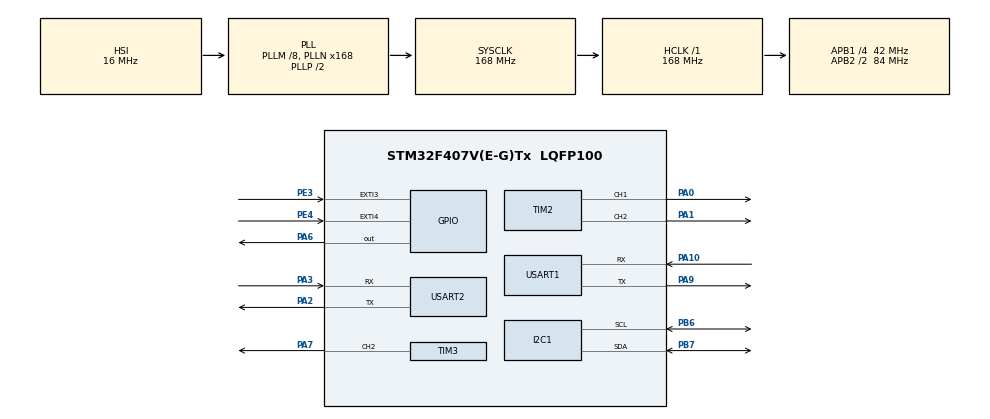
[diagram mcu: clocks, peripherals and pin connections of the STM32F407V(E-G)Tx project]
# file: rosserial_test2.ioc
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Dma.Request0=USART1_RX
Dma.Request1=USART1_TX
Dma.USART1_RX.0.Direction=DMA_PERIPH_TO_MEMORY
Dma.USART1_RX.0.FIFOMode=DMA_FIFOMODE_DISABLE
Dma.USART1_RX.0.Instance=DMA2_Stream2
Dma.USART1_RX.0.MemDataAlignment=DMA_MDATAALIGN_BYTE
Dma.USART1_RX.0.MemInc=DMA_MINC_ENABLE
Dma.USART1_RX.0.Mode=DMA_NORMAL
Dma.USART1_RX.0.PeriphDataAlignment=DMA_PDATAALIGN_BYTE
Dma.USART1_RX.0.PeriphInc=DMA_PINC_DISABLE
Dma.USART1_RX.0.Priority=DMA_PRIORITY_HIGH
Dma.USART1_TX.1.Direction=DMA_MEMORY_TO_PERIPH
Dma.USART1_TX.1.FIFOMode=DMA_FIFOMODE_DISABLE
Dma.USART1_TX.1.Instance=DMA2_Stream7
Dma.USART1_TX.1.MemDataAlignment=DMA_MDATAALIGN_BYTE
Dma.USART1_TX.1.MemInc=DMA_MINC_ENABLE
Dma.USART1_TX.1.Mode=DMA_NORMAL
Dma.USART1_TX.1.PeriphDataAlignment=DMA_PDATAALIGN_BYTE
Dma.USART1_TX.1.PeriphInc=DMA_PINC_DISABLE
Dma.USART1_TX.1.Priority=DMA_PRIORITY_HIGH
Mcu.Family=STM32F4
Mcu.Name=STM32F407V(E-G)Tx
Mcu.Package=LQFP100
NVIC.DMA2_Stream2_IRQn=true\:0\:0\:false\:false\:true\:false\:true
NVIC.DMA2_Stream7_IRQn=true\:0\:0\:false\:false\:true\:false\:true
NVIC.EXTI3_IRQn=true\:0\:0\:false\:false\:true\:true\:true
NVIC.EXTI4_IRQn=true\:0\:0\:false\:false\:true\:true\:true
NVIC.PriorityGroup=NVIC_PRIORITYGROUP_4
NVIC.USART1_IRQn=true\:0\:0\:false\:false\:true\:true\:true
PA0-WKUP.Signal=S_TIM2_CH1_ETR
PA1.Signal=S_TIM2_CH2
PA10.Mode=Asynchronous
PA10.Signal=USART1_RX
PA2.Mode=Asynchronous
PA2.Signal=USART2_TX
PA3.Mode=Asynchronous
PA3.Signal=USART2_RX
PA6.Signal=GPIO_Output
PA7.Signal=S_TIM3_CH2
PA9.Mode=Asynchronous
PA9.Signal=USART1_TX
PB6.Mode=I2C
PB6.Signal=I2C1_SCL
PB7.Mode=I2C
PB7.Signal=I2C1_SDA
PE3.Signal=GPXTI3
PE4.Signal=GPXTI4
PH0-OSC_IN.Mode=HSE-External-Oscillator
PH0-OSC_IN.Signal=RCC_OSC_IN
PH1-OSC_OUT.Mode=HSE-External-Oscillator
PH1-OSC_OUT.Signal=RCC_OSC_OUT
ProjectManager.HeapSize=0x200
ProjectManager.StackSize=0x400
ProjectManager.TargetToolchain=STM32CubeIDE
RCC.48MHZClocksFreq_Value=84000000
RCC.AHBFreq_Value=168000000
RCC.APB1CLKDivider=RCC_HCLK_DIV4
RCC.APB1Freq_Value=42000000
RCC.APB1TimFreq_Value=84000000
RCC.APB2CLKDivider=RCC_HCLK_DIV2
RCC.APB2Freq_Value=84000000
RCC.APB2TimFreq_Value=168000000
RCC.CortexFreq_Value=168000000
RCC.HCLKFreq_Value=168000000
RCC.HSE_VALUE=8000000
RCC.HSI_VALUE=16000000
RCC.LSE_VALUE=32768
RCC.PLLM=8
RCC.PLLN=168
RCC.SYSCLKFreq_VALUE=168000000
RCC.SYSCLKSource=RCC_SYSCLKSOURCE_PLLCLK
RCC.VCOOutputFreq_Value=336000000
SH.S_TIM2_CH1_ETR.0=TIM2_CH1,PWM Generation1 CH1
SH.S_TIM2_CH2.0=TIM2_CH2,PWM Generation2 CH2
SH.S_TIM3_CH2.0=TIM3_CH2,PWM Generation2 CH2
TIM2.Channel-PWM\ Generation1\ CH1=TIM_CHANNEL_1
TIM2.Channel-PWM\ Generation2\ CH2=TIM_CHANNEL_2
TIM3.Channel-PWM\ Generation2\ CH2=TIM_CHANNEL_2
USART1.VirtualMode=VM_ASYNC
USART2.VirtualMode=VM_ASYNC
VP_TIM2_VS_ClockSourceINT.Mode=Internal
VP_TIM3_VS_ClockSourceINT.Mode=Internal
board=custom

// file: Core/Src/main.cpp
/* USER CODE BEGIN Header */
/**
  ******************************************************************************
  * @file           : main.c
  * @brief          : Main program body
  ******************************************************************************
  * @attention
  *
  * <h2><center>&copy; Copyright (c) 2020 STMicroelectronics.
  * All rights reserved.</center></h2>
  *
  * This software component is licensed by ST under BSD 3-Clause license,
  * the "License"; You may not use this file except in compliance with the
  * License. You may obtain a copy of the License at:
  *                        opensource.org/licenses/BSD-3-Clause
  *
  ******************************************************************************
  */
/* USER CODE END Header */

#include "main.h"
#include <ros.h>
#include <std_msgs/String.h>

ros::NodeHandle nh;

std_msgs::String str_msg;
ros::Publisher chatter("chatter", &str_msg);
char hello[] = "Hello world!";

void HAL_UART_TxCpltCallback(UART_HandleTypeDef *huart){
  nh.getHardware()->flush();
}

void HAL_UART_RxCpltCallback(UART_HandleTypeDef *huart){
  nh.getHardware()->reset_rbuf();
}

I2C_HandleTypeDef hi2c1;

TIM_HandleTypeDef htim2;
TIM_HandleTypeDef htim3;

UART_HandleTypeDef huart1;
UART_HandleTypeDef huart2;
DMA_HandleTypeDef hdma_usart1_rx;
DMA_HandleTypeDef hdma_usart1_tx;

void SystemClock_Config(void);
static void MX_GPIO_Init(void);
static void MX_I2C1_Init(void);
static void MX_TIM2_Init(void);
static void MX_TIM3_Init(void);
static void MX_DMA_Init(void);
static void MX_USART1_UART_Init(void);
static void MX_USART2_UART_Init(void);

int main(void)
{

  /* MCU Configuration--------------------------------------------------------*/

  /* Reset of all peripherals, Initializes the Flash interface and the Systick. */
  HAL_Init();

  /* Configure the system clock */
  SystemClock_Config();

  /* Initialize all configured peripherals */
  MX_GPIO_Init();
  MX_DMA_Init();
  MX_I2C1_Init();
  MX_TIM2_Init();
  MX_TIM3_Init();
  MX_USART1_UART_Init();
  MX_USART2_UART_Init();
  /* USER CODE BEGIN 2 */
  nh.initNode();
  nh.advertise(chatter);
  HAL_TIM_PWM_Start(&htim2, TIM_CHANNEL_1);
  HAL_TIM_PWM_Start(&htim2, TIM_CHANNEL_2);
  HAL_TIM_PWM_Start(&htim3, TIM_CHANNEL_2);
  /* USER CODE END 2 */

  /* Infinite loop */
  /* USER CODE BEGIN WHILE */
  uint16_t ccr = 0;
  while (1)
  {
    /* USER CODE END WHILE */
	  str_msg.data = hello;
	  chatter.publish(&str_msg);

	  TIM3->CCR2 = ccr;
	  ccr += 1000;
	  if (ccr > TIM3->ARR) ccr = 0;
//	  HAL_GPIO_WritePin(GPIOA, GPIO_PIN_6, GPIO_PIN_RESET);
//	  HAL_Delay(2000);
//
//	  HAL_GPIO_WritePin(GPIOA, GPIO_PIN_6, GPIO_PIN_SET);

	  nh.spinOnce();
	  HAL_Delay(50);
  }
}

void SystemClock_Config(void)
{
  RCC_OscInitTypeDef RCC_OscInitStruct = {0};
  RCC_ClkInitTypeDef RCC_ClkInitStruct = {0};

  /** Configure the main internal regulator output voltage
  */
  __HAL_RCC_PWR_CLK_ENABLE();
  __HAL_PWR_VOLTAGESCALING_CONFIG(PWR_REGULATOR_VOLTAGE_SCALE1);
  /** Initializes the CPU, AHB and APB busses clocks
  */
  RCC_OscInitStruct.OscillatorType = RCC_OSCILLATORTYPE_HSI;
  RCC_OscInitStruct.HSIState = RCC_HSI_ON;
  RCC_OscInitStruct.HSICalibrationValue = RCC_HSICALIBRATION_DEFAULT;
  RCC_OscInitStruct.PLL.PLLState = RCC_PLL_ON;
  RCC_OscInitStruct.PLL.PLLSource = RCC_PLLSOURCE_HSI;
  RCC_OscInitStruct.PLL.PLLM = 8;
  RCC_OscInitStruct.PLL.PLLN = 168;
  RCC_OscInitStruct.PLL.PLLP = RCC_PLLP_DIV2;
  RCC_OscInitStruct.PLL.PLLQ = 4;
  if (HAL_RCC_OscConfig(&RCC_OscInitStruct) != HAL_OK)
  {
    Error_Handler();
  }
  /** Initializes the CPU, AHB and APB busses clocks
  */
  RCC_ClkInitStruct.ClockType = RCC_CLOCKTYPE_HCLK|RCC_CLOCKTYPE_SYSCLK
                              |RCC_CLOCKTYPE_PCLK1|RCC_CLOCKTYPE_PCLK2;
  RCC_ClkInitStruct.SYSCLKSource = RCC_SYSCLKSOURCE_PLLCLK;
  RCC_ClkInitStruct.AHBCLKDivider = RCC_SYSCLK_DIV1;
  RCC_ClkInitStruct.APB1CLKDivider = RCC_HCLK_DIV4;
  RCC_ClkInitStruct.APB2CLKDivider = RCC_HCLK_DIV2;

  if (HAL_RCC_ClockConfig(&RCC_ClkInitStruct, FLASH_LATENCY_5) != HAL_OK)
  {
    Error_Handler();
  }
}

static void MX_I2C1_Init(void)
{

  hi2c1.Instance = I2C1;
  hi2c1.Init.ClockSpeed = 100000;
  hi2c1.Init.DutyCycle = I2C_DUTYCYCLE_2;
  hi2c1.Init.OwnAddress1 = 0;
  hi2c1.Init.AddressingMode = I2C_ADDRESSINGMODE_7BIT;
  hi2c1.Init.DualAddressMode = I2C_DUALADDRESS_DISABLE;
  hi2c1.Init.OwnAddress2 = 0;
  hi2c1.Init.GeneralCallMode = I2C_GENERALCALL_DISABLE;
  hi2c1.Init.NoStretchMode = I2C_NOSTRETCH_DISABLE;
  if (HAL_I2C_Init(&hi2c1) != HAL_OK)
  {
    Error_Handler();
  }

}

static void MX_TIM2_Init(void)
{

  TIM_ClockConfigTypeDef sClockSourceConfig = {0};
  TIM_MasterConfigTypeDef sMasterConfig = {0};
  TIM_OC_InitTypeDef sConfigOC = {0};

  htim2.Instance = TIM2;
  htim2.Init.Prescaler = 20-1;
  htim2.Init.CounterMode = TIM_COUNTERMODE_UP;
  htim2.Init.Period = 42000-1;
  htim2.Init.ClockDivision = TIM_CLOCKDIVISION_DIV1;
  htim2.Init.AutoReloadPreload = TIM_AUTORELOAD_PRELOAD_DISABLE;
  if (HAL_TIM_Base_Init(&htim2) != HAL_OK)
  {
    Error_Handler();
  }
  sClockSourceConfig.ClockSource = TIM_CLOCKSOURCE_INTERNAL;
  if (HAL_TIM_ConfigClockSource(&htim2, &sClockSourceConfig) != HAL_OK)
  {
    Error_Handler();
  }
  if (HAL_TIM_PWM_Init(&htim2) != HAL_OK)
  {
    Error_Handler();
  }
  sMasterConfig.MasterOutputTrigger = TIM_TRGO_RESET;
  sMasterConfig.MasterSlaveMode = TIM_MASTERSLAVEMODE_DISABLE;
  if (HAL_TIMEx_MasterConfigSynchronization(&htim2, &sMasterConfig) != HAL_OK)
  {
    Error_Handler();
  }
  sConfigOC.OCMode = TIM_OCMODE_PWM1;
  sConfigOC.Pulse = 21000-1;
  sConfigOC.OCPolarity = TIM_OCPOLARITY_HIGH;
  sConfigOC.OCFastMode = TIM_OCFAST_DISABLE;
  if (HAL_TIM_PWM_ConfigChannel(&htim2, &sConfigOC, TIM_CHANNEL_1) != HAL_OK)
  {
    Error_Handler();
  }
  sConfigOC.Pulse = 10500-1;
  if (HAL_TIM_PWM_ConfigChannel(&htim2, &sConfigOC, TIM_CHANNEL_2) != HAL_OK)
  {
    Error_Handler();
  }
  HAL_TIM_MspPostInit(&htim2);

}

static void MX_TIM3_Init(void)
{

  TIM_ClockConfigTypeDef sClockSourceConfig = {0};
  TIM_MasterConfigTypeDef sMasterConfig = {0};
  TIM_OC_InitTypeDef sConfigOC = {0};

  htim3.Instance = TIM3;
  htim3.Init.Prescaler = 20-1; // 주기
  htim3.Init.CounterMode = TIM_COUNTERMODE_UP;
  htim3.Init.Period = 42000-1;
  htim3.Init.ClockDivision = TIM_CLOCKDIVISION_DIV1;
  htim3.Init.AutoReloadPreload = TIM_AUTORELOAD_PRELOAD_DISABLE;
  if (HAL_TIM_Base_Init(&htim3) != HAL_OK)
  {
    Error_Handler();
  }
  sClockSourceConfig.ClockSource = TIM_CLOCKSOURCE_INTERNAL;
  if (HAL_TIM_ConfigClockSource(&htim3, &sClockSourceConfig) != HAL_OK)
  {
    Error_Handler();
  }
  if (HAL_TIM_PWM_Init(&htim3) != HAL_OK)
  {
    Error_Handler();
  }
  sMasterConfig.MasterOutputTrigger = TIM_TRGO_RESET;
  sMasterConfig.MasterSlaveMode = TIM_MASTERSLAVEMODE_DISABLE;
  if (HAL_TIMEx_MasterConfigSynchronization(&htim3, &sMasterConfig) != HAL_OK)
  {
    Error_Handler();
  }
  sConfigOC.OCMode = TIM_OCMODE_PWM1;
  sConfigOC.Pulse = 21000-1;// 펄스 폭
  sConfigOC.OCPolarity = TIM_OCPOLARITY_HIGH;
  sConfigOC.OCFastMode = TIM_OCFAST_DISABLE;
  if (HAL_TIM_PWM_ConfigChannel(&htim3, &sConfigOC, TIM_CHANNEL_1) != HAL_OK)
  {
    Error_Handler();
  }
  if (HAL_TIM_PWM_ConfigChannel(&htim3, &sConfigOC, TIM_CHANNEL_2) != HAL_OK)
  {
    Error_Handler();
  }
  HAL_TIM_MspPostInit(&htim3);

}

static void MX_USART1_UART_Init(void)
{

  huart1.Instance = USART1;
  huart1.Init.BaudRate = 115200;
  huart1.Init.WordLength = UART_WORDLENGTH_8B;
  huart1.Init.StopBits = UART_STOPBITS_1;
  huart1.Init.Parity = UART_PARITY_NONE;
  huart1.Init.Mode = UART_MODE_TX_RX;
  huart1.Init.HwFlowCtl = UART_HWCONTROL_NONE;
  huart1.Init.OverSampling = UART_OVERSAMPLING_16;
  if (HAL_UART_Init(&huart1) != HAL_OK)
  {
    Error_Handler();
  }

}

static void MX_USART2_UART_Init(void)
{

  huart2.Instance = USART2;
  huart2.Init.BaudRate = 115200;
  huart2.Init.WordLength = UART_WORDLENGTH_8B;
  huart2.Init.StopBits = UART_STOPBITS_1;
  huart2.Init.Parity = UART_PARITY_NONE;
  huart2.Init.Mode = UART_MODE_TX_RX;
  huart2.Init.HwFlowCtl = UART_HWCONTROL_NONE;
  huart2.Init.OverSampling = UART_OVERSAMPLING_16;
  if (HAL_UART_Init(&huart2) != HAL_OK)
  {
    Error_Handler();
  }

}

static void MX_DMA_Init(void)
{

  /* DMA controller clock enable */
  __HAL_RCC_DMA2_CLK_ENABLE();

  /* DMA interrupt init */
  /* DMA2_Stream2_IRQn interrupt configuration */
  HAL_NVIC_SetPriority(DMA2_Stream2_IRQn, 0, 0);
  HAL_NVIC_EnableIRQ(DMA2_Stream2_IRQn);
  /* DMA2_Stream7_IRQn interrupt configuration */
  HAL_NVIC_SetPriority(DMA2_Stream7_IRQn, 0, 0);
  HAL_NVIC_EnableIRQ(DMA2_Stream7_IRQn);

}

static void MX_GPIO_Init(void)
{

  GPIO_InitTypeDef GPIO_InitStruct = {0};
  /* GPIO Ports Clock Enable */
  __HAL_RCC_GPIOE_CLK_ENABLE();
  __HAL_RCC_GPIOH_CLK_ENABLE();
  __HAL_RCC_GPIOA_CLK_ENABLE();
  __HAL_RCC_GPIOB_CLK_ENABLE();

  /*Configure GPIO pins : PE3 PE4 */
  GPIO_InitStruct.Pin = GPIO_PIN_3|GPIO_PIN_4;
  GPIO_InitStruct.Mode = GPIO_MODE_IT_RISING;
  GPIO_InitStruct.Pull = GPIO_NOPULL;
  HAL_GPIO_Init(GPIOE, &GPIO_InitStruct);

  /*Configure GPIO pin : PA6 */
  GPIO_InitStruct.Pin = GPIO_PIN_6;
  GPIO_InitStruct.Mode = GPIO_MODE_OUTPUT_PP;
  GPIO_InitStruct.Pull = GPIO_NOPULL;
  GPIO_InitStruct.Speed = GPIO_SPEED_FREQ_LOW;
  HAL_GPIO_Init(GPIOA, &GPIO_InitStruct);

  /*Configure GPIO pin Output Level */
  HAL_GPIO_WritePin(GPIOA, GPIO_PIN_6, GPIO_PIN_RESET);

  /* EXTI interrupt init*/
  HAL_NVIC_SetPriority(EXTI3_IRQn, 0, 0);
  HAL_NVIC_EnableIRQ(EXTI3_IRQn);

  HAL_NVIC_SetPriority(EXTI4_IRQn, 0, 0);
  HAL_NVIC_EnableIRQ(EXTI4_IRQn);

}

void Error_Handler(void)
{
}

/************************ (C) COPYRIGHT STMicroelectronics *****END OF FILE****/
